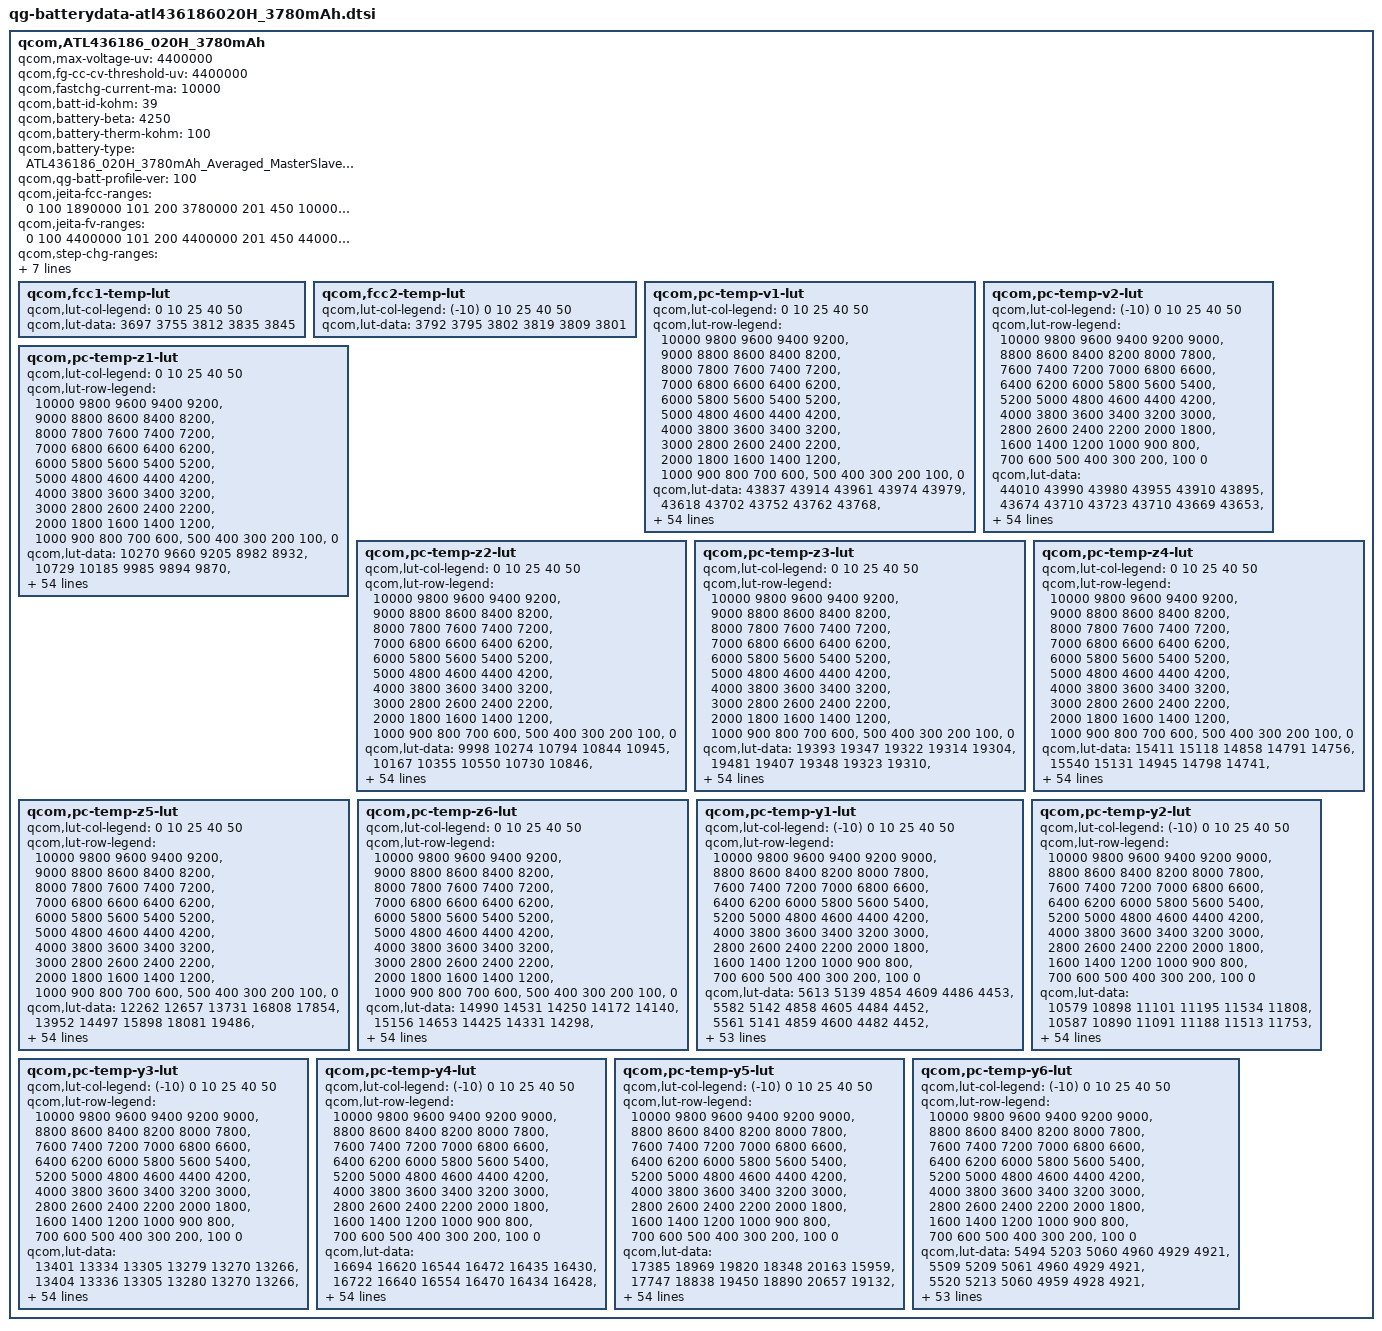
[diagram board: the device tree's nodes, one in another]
qcom,ATL436186_020H_3780mAh {
	/* ATL436186_020H_3780mAh_Averaged_MasterSlave_Feb25th2020 */
	qcom,max-voltage-uv = <4400000>;
	qcom,fg-cc-cv-threshold-uv = <4400000>;
	qcom,fastchg-current-ma = <10000>;
	qcom,batt-id-kohm = <39>;
	qcom,battery-beta = <4250>;
	qcom,battery-therm-kohm = <100>;
	qcom,battery-type =
			"ATL436186_020H_3780mAh_Averaged_MasterSlave_Feb25th2020";
	qcom,qg-batt-profile-ver = <100>;

	qcom,jeita-fcc-ranges = <0  100  1890000
				101 200  3780000
				201 450  10000000
				451 550  1890000>;

	qcom,jeita-fv-ranges = <0   100  4400000
				101 200  4400000
				201 450  4400000
				451 550  4050000>;

	qcom,step-chg-ranges = <3500000  4000000  10000000
				4000001  4200000  8000000
				4200001  4400000  6000000>;
	qcom,ocv-based-step-chg;

	/* COOL = 10 degc, WARM = 45 degC */
	qcom,jeita-soft-thresholds = <0x4ccc 0x20b8>;
	/* COLD = 0 degC, HOT = 55 degC*/
	qcom,jeita-hard-thresholds = <0x58cd 0x181d>;
	/* COOL hys = 13 degC, WARM hys = 42 degC */
	qcom,jeita-soft-hys-thresholds = <0x48d4 0x23c0>;
	qcom,jeita-soft-fcc-ua = <1890000 1890000>;
	qcom,jeita-soft-fv-uv = <4400000 4050000>;

	qcom,fcc1-temp-lut {
		qcom,lut-col-legend = <0 10 25 40 50>;
		qcom,lut-data = <3697 3755 3812 3835 3845>;
	};

	qcom,fcc2-temp-lut {
		qcom,lut-col-legend = <(-10) 0 10 25 40 50>;
		qcom,lut-data = <3792 3795 3802 3819 3809 3801>;
	};

	qcom,pc-temp-v1-lut {
		qcom,lut-col-legend = <0 10 25 40 50>;
		qcom,lut-row-legend = <10000 9800 9600 9400 9200>,
			<9000 8800 8600 8400 8200>,
			<8000 7800 7600 7400 7200>,
			<7000 6800 6600 6400 6200>,
			<6000 5800 5600 5400 5200>,
			<5000 4800 4600 4400 4200>,
			<4000 3800 3600 3400 3200>,
			<3000 2800 2600 2400 2200>,
			<2000 1800 1600 1400 1200>,
			<1000 900 800 700 600>,
			<500 400 300 200 100>,
			<0>;
		qcom,lut-data = <43837 43914 43961 43974 43979>,
			<43618 43702 43752 43762 43768>,
			<43394 43485 43537 43549 43556>,
			<43166 43264 43318 43332 43342>,
			<42938 43039 43095 43113 43125>,
			<42710 42810 42869 42890 42903>,
			<42481 42578 42639 42662 42677>,
			<42256 42346 42406 42431 42450>,
			<42034 42119 42176 42201 42223>,
			<41817 41896 41949 41975 41997>,
			<41609 41677 41725 41751 41771>,
			<41407 41462 41506 41531 41550>,
			<41207 41252 41291 41313 41332>,
			<41011 41053 41083 41103 41121>,
			<40819 40863 40881 40898 40917>,
			<40625 40675 40686 40700 40720>,
			<40431 40487 40499 40510 40529>,
			<40258 40304 40321 40329 40345>,
			<40119 40139 40148 40153 40167>,
			<39977 39988 39986 39986 39997>,
			<39774 39809 39817 39819 39828>,
			<39506 39562 39607 39622 39634>,
			<39289 39314 39366 39391 39406>,
			<39151 39148 39169 39185 39199>,
			<39041 39021 39021 39027 39039>,
			<38943 38908 38896 38893 38903>,
			<38856 38802 38783 38774 38781>,
			<38774 38706 38682 38669 38673>,
			<38695 38620 38590 38572 38573>,
			<38621 38542 38505 38481 38478>,
			<38554 38471 38429 38398 38392>,
			<38493 38405 38359 38322 38312>,
			<38438 38346 38296 38252 38238>,
			<38387 38291 38238 38189 38170>,
			<38341 38243 38188 38137 38109>,
			<38300 38198 38138 38084 38049>,
			<38266 38162 38090 38022 37975>,
			<38227 38123 38040 37953 37891>,
			<38155 38058 37972 37872 37800>,
			<38045 37951 37874 37776 37702>,
			<37922 37829 37759 37666 37594>,
			<37785 37699 37633 37539 37465>,
			<37631 37552 37490 37396 37318>,
			<37448 37375 37320 37231 37158>,
			<37301 37226 37175 37102 37032>,
			<37200 37139 37097 37033 36972>,
			<37176 37110 37072 37016 36954>,
			<37175 37095 37054 37001 36939>,
			<37137 37069 37036 36980 36914>,
			<37063 36993 36930 36851 36764>,
			<36758 36680 36593 36504 36417>,
			<36291 36221 36130 36040 35954>,
			<35695 35625 35535 35440 35357>,
			<34884 34815 34721 34626 34546>,
			<33616 33554 33462 33363 33302>,
			<30000 30000 30000 30000 30000>;
	};

	qcom,pc-temp-v2-lut {
		qcom,lut-col-legend = <(-10) 0 10 25 40 50>;
		qcom,lut-row-legend = <10000 9800 9600 9400 9200 9000>,
			<8800 8600 8400 8200 8000 7800>,
			<7600 7400 7200 7000 6800 6600>,
			<6400 6200 6000 5800 5600 5400>,
			<5200 5000 4800 4600 4400 4200>,
			<4000 3800 3600 3400 3200 3000>,
			<2800 2600 2400 2200 2000 1800>,
			<1600 1400 1200 1000 900 800>,
			<700 600 500 400 300 200>,
			<100 0>;
		qcom,lut-data = <44010 43990 43980 43955 43910 43895>,
			<43674 43710 43723 43710 43669 43653>,
			<43367 43445 43475 43472 43433 43418>,
			<43093 43196 43238 43240 43203 43189>,
			<42851 42966 43012 43017 42980 42968>,
			<42613 42737 42786 42792 42757 42746>,
			<42365 42504 42555 42562 42527 42517>,
			<42121 42270 42323 42330 42297 42288>,
			<41898 42038 42094 42100 42070 42062>,
			<41692 41806 41864 41873 41844 41837>,
			<41486 41578 41638 41648 41621 41615>,
			<41265 41355 41418 41427 41403 41397>,
			<41047 41138 41202 41209 41188 41182>,
			<40862 40936 40996 41001 40980 40975>,
			<40707 40746 40796 40798 40776 40772>,
			<40521 40559 40598 40601 40580 40577>,
			<40232 40377 40403 40410 40392 40389>,
			<39909 40189 40207 40224 40211 40207>,
			<39657 39968 40007 40045 40036 40032>,
			<39447 39713 39804 39870 39866 39866>,
			<39247 39471 39594 39674 39679 39682>,
			<39047 39253 39364 39429 39442 39449>,
			<38856 39052 39141 39188 39206 39213>,
			<38674 38878 38961 39005 39025 39033>,
			<38496 38724 38807 38848 38871 38882>,
			<38358 38586 38671 38714 38738 38751>,
			<38264 38460 38551 38597 38623 38636>,
			<38190 38345 38443 38492 38520 38532>,
			<38129 38232 38342 38395 38426 38435>,
			<38078 38123 38247 38304 38337 38344>,
			<38030 38040 38160 38220 38255 38261>,
			<37982 37980 38078 38142 38179 38186>,
			<37935 37931 38002 38068 38106 38114>,
			<37884 37893 37933 38000 38035 38038>,
			<37832 37863 37868 37935 37964 37959>,
			<37777 37829 37812 37862 37879 37865>,
			<37715 37789 37766 37778 37771 37744>,
			<37646 37742 37719 37690 37659 37617>,
			<37568 37678 37654 37600 37560 37514>,
			<37480 37592 37571 37507 37468 37423>,
			<37378 37484 37472 37409 37367 37324>,
			<37250 37342 37350 37301 37256 37212>,
			<37117 37183 37208 37173 37128 37083>,
			<36996 37011 37048 37022 36979 36931>,
			<36898 36881 36926 36922 36889 36842>,
			<36814 36811 36868 36890 36863 36817>,
			<36773 36779 36838 36869 36848 36802>,
			<36727 36738 36803 36842 36825 36779>,
			<36660 36680 36748 36790 36781 36737>,
			<36517 36561 36624 36620 36609 36535>,
			<36231 36271 36298 36228 36203 36133>,
			<35764 35780 35781 35692 35681 35615>,
			<35118 35133 35110 35007 35009 34946>,
			<34216 34250 34193 34048 34114 34057>,
			<32787 32833 32800 32877 32759 32761>,
			<29558 29605 29729 29539 29540 29544>;
	};

	qcom,pc-temp-z1-lut {
		qcom,lut-col-legend = <0 10 25 40 50>;
		qcom,lut-row-legend = <10000 9800 9600 9400 9200>,
			<9000 8800 8600 8400 8200>,
			<8000 7800 7600 7400 7200>,
			<7000 6800 6600 6400 6200>,
			<6000 5800 5600 5400 5200>,
			<5000 4800 4600 4400 4200>,
			<4000 3800 3600 3400 3200>,
			<3000 2800 2600 2400 2200>,
			<2000 1800 1600 1400 1200>,
			<1000 900 800 700 600>,
			<500 400 300 200 100>,
			<0>;
		qcom,lut-data = <10270 9660 9205 8982 8932>,
			<10729 10185 9985 9894 9870>,
			<10961 10522 10161 10008 9971>,
			<11078 10616 10231 10065 10021>,
			<11137 10656 10248 10073 10030>,
			<11151 10675 10258 10073 10030>,
			<11155 10683 10258 10073 10029>,
			<11157 10687 10253 10071 10028>,
			<11160 10685 10249 10068 10027>,
			<11164 10677 10247 10067 10027>,
			<11163 10670 10245 10066 10026>,
			<11158 10666 10244 10066 10026>,
			<11155 10663 10242 10066 10026>,
			<11156 10660 10241 10066 10026>,
			<11157 10657 10242 10066 10026>,
			<11156 10656 10243 10066 10026>,
			<11151 10657 10244 10066 10027>,
			<11148 10661 10245 10067 10028>,
			<11149 10661 10246 10069 10029>,
			<11150 10662 10249 10070 10030>,
			<11154 10662 10251 10071 10030>,
			<11163 10665 10253 10073 10031>,
			<11167 10668 10256 10075 10032>,
			<11169 10672 10259 10077 10033>,
			<11173 10677 10263 10079 10035>,
			<11179 10682 10268 10081 10037>,
			<11187 10688 10272 10083 10039>,
			<11191 10694 10276 10084 10040>,
			<11188 10695 10280 10086 10041>,
			<11182 10696 10284 10089 10042>,
			<11180 10697 10287 10091 10044>,
			<11182 10699 10290 10093 10046>,
			<11186 10703 10294 10095 10047>,
			<11195 10707 10298 10098 10048>,
			<11210 10711 10302 10101 10050>,
			<11214 10715 10307 10104 10052>,
			<11209 10725 10311 10107 10054>,
			<11204 10735 10316 10109 10057>,
			<11209 10736 10321 10112 10059>,
			<11224 10733 10326 10114 10060>,
			<11232 10731 10331 10116 10062>,
			<11233 10740 10335 10119 10063>,
			<11234 10751 10340 10121 10065>,
			<11236 10753 10345 10123 10065>,
			<11250 10761 10351 10125 10066>,
			<11246 10766 10354 10126 10067>,
			<11246 10761 10358 10127 10067>,
			<11257 10768 10360 10127 10067>,
			<11246 10764 10362 10128 10068>,
			<11264 10770 10369 10131 10069>,
			<11271 10785 10373 10132 10072>,
			<11301 10793 10379 10137 10073>,
			<11283 10797 10389 10144 10076>,
			<11343 10815 10399 10147 10080>,
			<11343 10815 10399 10147 10080>,
			<11343 10815 10399 10147 10080>;
	};

	qcom,pc-temp-z2-lut {
		qcom,lut-col-legend = <0 10 25 40 50>;
		qcom,lut-row-legend = <10000 9800 9600 9400 9200>,
			<9000 8800 8600 8400 8200>,
			<8000 7800 7600 7400 7200>,
			<7000 6800 6600 6400 6200>,
			<6000 5800 5600 5400 5200>,
			<5000 4800 4600 4400 4200>,
			<4000 3800 3600 3400 3200>,
			<3000 2800 2600 2400 2200>,
			<2000 1800 1600 1400 1200>,
			<1000 900 800 700 600>,
			<500 400 300 200 100>,
			<0>;
		qcom,lut-data = <9998 10274 10794 10844 10945>,
			<10167 10355 10550 10730 10846>,
			<10239 10399 10603 10678 10871>,
			<10266 10395 10627 10658 10860>,
			<10276 10383 10590 10661 10840>,
			<10258 10382 10530 10681 10820>,
			<10229 10393 10504 10694 10818>,
			<10222 10402 10503 10691 10838>,
			<10225 10403 10506 10686 10861>,
			<10230 10402 10495 10698 10866>,
			<10468 10399 10479 10712 10863>,
			<10817 10392 10478 10717 10858>,
			<10830 10389 10490 10720 10866>,
			<10488 10389 10497 10723 10887>,
			<10237 10383 10489 10733 10919>,
			<10238 10380 10479 10753 10955>,
			<10250 10394 10485 10763 10976>,
			<10293 10409 10508 10767 10990>,
			<10590 10407 10522 10769 10998>,
			<10856 10392 10525 10764 10996>,
			<10737 10386 10523 10757 10989>,
			<10407 10410 10531 10746 10961>,
			<10271 10437 10570 10711 10841>,
			<10271 10447 10592 10670 10746>,
			<10273 10453 10576 10628 10731>,
			<10283 10454 10553 10595 10727>,
			<10306 10441 10542 10604 10733>,
			<10322 10425 10536 10639 10758>,
			<10324 10424 10535 10657 10785>,
			<10323 10434 10540 10663 10803>,
			<10323 10447 10549 10671 10824>,
			<10329 10467 10557 10698 10870>,
			<10336 10487 10569 10749 10948>,
			<10345 10497 10586 10795 11004>,
			<10355 10502 10622 10833 11059>,
			<10358 10503 10654 10871 11110>,
			<10355 10506 10670 10914 11142>,
			<10351 10511 10681 10958 11183>,
			<10348 10514 10696 10979 11193>,
			<10344 10522 10730 10992 11177>,
			<10338 10526 10756 11000 11154>,
			<10307 10496 10725 10996 11137>,
			<10278 10462 10682 10987 11119>,
			<10264 10453 10689 10977 11087>,
			<10246 10428 10699 10978 11047>,
			<10229 10374 10720 11010 11096>,
			<10188 10355 10691 11025 11117>,
			<10121 10306 10709 11029 11193>,
			<10243 10335 10714 11081 11268>,
			<10479 10337 10724 10961 10999>,
			<10405 10348 10693 10847 10883>,
			<10327 10360 10632 10748 10808>,
			<9992 10290 10623 10696 10740>,
			<10016 10209 10570 10627 10634>,
			<10016 10209 10570 10627 10634>,
			<10016 10209 10570 10627 10634>;
	};

	qcom,pc-temp-z3-lut {
		qcom,lut-col-legend = <0 10 25 40 50>;
		qcom,lut-row-legend = <10000 9800 9600 9400 9200>,
			<9000 8800 8600 8400 8200>,
			<8000 7800 7600 7400 7200>,
			<7000 6800 6600 6400 6200>,
			<6000 5800 5600 5400 5200>,
			<5000 4800 4600 4400 4200>,
			<4000 3800 3600 3400 3200>,
			<3000 2800 2600 2400 2200>,
			<2000 1800 1600 1400 1200>,
			<1000 900 800 700 600>,
			<500 400 300 200 100>,
			<0>;
		qcom,lut-data = <19393 19347 19322 19314 19304>,
			<19481 19407 19348 19323 19310>,
			<19528 19444 19374 19334 19318>,
			<19557 19459 19384 19340 19321>,
			<19571 19467 19381 19338 19320>,
			<19574 19469 19375 19332 19319>,
			<19576 19464 19371 19330 19317>,
			<19574 19458 19367 19329 19315>,
			<19563 19453 19365 19329 19313>,
			<19554 19448 19361 19327 19312>,
			<19555 19445 19358 19323 19311>,
			<19558 19444 19356 19321 19310>,
			<19555 19442 19354 19320 19310>,
			<19544 19439 19353 19319 19309>,
			<19533 19433 19353 19318 19306>,
			<19526 19431 19353 19318 19302>,
			<19521 19432 19352 19317 19300>,
			<19520 19434 19351 19315 19300>,
			<19527 19434 19350 19314 19299>,
			<19535 19434 19349 19312 19299>,
			<19537 19434 19349 19311 19299>,
			<19543 19435 19353 19313 19303>,
			<19546 19436 19361 19324 19317>,
			<19536 19440 19369 19333 19326>,
			<19524 19451 19377 19336 19325>,
			<19524 19456 19381 19338 19323>,
			<19532 19456 19380 19338 19321>,
			<19538 19454 19377 19335 19319>,
			<19538 19451 19374 19332 19317>,
			<19537 19445 19369 19330 19315>,
			<19535 19440 19365 19327 19312>,
			<19531 19436 19361 19324 19309>,
			<19527 19434 19358 19321 19306>,
			<19524 19432 19356 19318 19303>,
			<19521 19430 19355 19315 19301>,
			<19519 19429 19354 19313 19300>,
			<19515 19426 19353 19312 19300>,
			<19511 19424 19352 19312 19301>,
			<19506 19420 19350 19312 19301>,
			<19499 19415 19347 19313 19303>,
			<19494 19410 19343 19314 19304>,
			<19492 19407 19342 19315 19306>,
			<19489 19404 19341 19316 19307>,
			<19483 19400 19338 19319 19308>,
			<19461 19390 19335 19317 19308>,
			<19456 19383 19327 19309 19299>,
			<19436 19385 19328 19304 19295>,
			<19263 19371 19326 19300 19292>,
			<19262 19374 19319 19296 19290>,
			<19261 19369 19326 19308 19301>,
			<19261 19365 19335 19313 19303>,
			<19261 19355 19338 19313 19303>,
			<19264 19362 19329 19315 19304>,
			<19263 19368 19332 19316 19306>,
			<19263 19368 19332 19316 19306>,
			<19263 19368 19332 19316 19306>;
	};

	qcom,pc-temp-z4-lut {
		qcom,lut-col-legend = <0 10 25 40 50>;
		qcom,lut-row-legend = <10000 9800 9600 9400 9200>,
			<9000 8800 8600 8400 8200>,
			<8000 7800 7600 7400 7200>,
			<7000 6800 6600 6400 6200>,
			<6000 5800 5600 5400 5200>,
			<5000 4800 4600 4400 4200>,
			<4000 3800 3600 3400 3200>,
			<3000 2800 2600 2400 2200>,
			<2000 1800 1600 1400 1200>,
			<1000 900 800 700 600>,
			<500 400 300 200 100>,
			<0>;
		qcom,lut-data = <15411 15118 14858 14791 14756>,
			<15540 15131 14945 14798 14741>,
			<15522 15130 14892 14768 14727>,
			<15372 15081 14836 14731 14698>,
			<15215 14972 14795 14714 14687>,
			<15110 14894 14763 14705 14683>,
			<15022 14847 14748 14697 14679>,
			<14959 14816 14739 14690 14675>,
			<14908 14802 14731 14684 14670>,
			<14869 14794 14723 14679 14665>,
			<14839 14788 14717 14674 14661>,
			<14817 14781 14710 14669 14656>,
			<14812 14775 14704 14663 14651>,
			<14820 14769 14698 14658 14647>,
			<14832 14763 14693 14652 14643>,
			<14850 14762 14688 14647 14640>,
			<14880 14770 14686 14643 14636>,
			<14889 14779 14685 14640 14631>,
			<14846 14773 14684 14639 14628>,
			<14800 14754 14688 14641 14629>,
			<14825 14750 14695 14648 14632>,
			<14928 14825 14724 14663 14641>,
			<14993 14913 14779 14695 14664>,
			<15001 14914 14799 14712 14678>,
			<14998 14879 14781 14707 14677>,
			<14983 14850 14758 14697 14673>,
			<14949 14834 14746 14689 14669>,
			<14924 14823 14738 14683 14664>,
			<14914 14821 14734 14678 14660>,
			<14908 14820 14732 14673 14656>,
			<14907 14819 14731 14670 14652>,
			<14908 14821 14731 14669 14650>,
			<14909 14823 14731 14668 14648>,
			<14909 14826 14732 14668 14647>,
			<14909 14829 14734 14669 14646>,
			<14909 14831 14738 14670 14646>,
			<14902 14827 14742 14676 14650>,
			<14892 14820 14745 14686 14661>,
			<14881 14812 14746 14689 14665>,
			<14868 14804 14742 14686 14662>,
			<14851 14792 14736 14681 14659>,
			<14827 14773 14724 14676 14657>,
			<14801 14751 14709 14671 14655>,
			<14776 14733 14701 14668 14655>,
			<14722 14697 14683 14659 14649>,
			<14692 14666 14659 14644 14634>,
			<14706 14660 14649 14639 14629>,
			<14871 14659 14641 14630 14620>,
			<14866 14650 14633 14626 14617>,
			<14863 14655 14638 14628 14623>,
			<14867 14664 14635 14630 14625>,
			<14872 14672 14633 14629 14625>,
			<14872 14667 14638 14627 14624>,
			<14877 14663 14636 14625 14622>,
			<14877 14663 14636 14625 14622>,
			<14877 14663 14636 14625 14622>;
	};

	qcom,pc-temp-z5-lut {
		qcom,lut-col-legend = <0 10 25 40 50>;
		qcom,lut-row-legend = <10000 9800 9600 9400 9200>,
			<9000 8800 8600 8400 8200>,
			<8000 7800 7600 7400 7200>,
			<7000 6800 6600 6400 6200>,
			<6000 5800 5600 5400 5200>,
			<5000 4800 4600 4400 4200>,
			<4000 3800 3600 3400 3200>,
			<3000 2800 2600 2400 2200>,
			<2000 1800 1600 1400 1200>,
			<1000 900 800 700 600>,
			<500 400 300 200 100>,
			<0>;
		qcom,lut-data = <12262 12657 13731 16808 17854>,
			<13952 14497 15898 18081 19486>,
			<15214 16021 17443 19818 21650>,
			<16162 17186 18570 21296 23275>,
			<17097 18170 19329 21536 24003>,
			<18157 19258 19745 21509 24358>,
			<19290 20662 19830 21628 24381>,
			<20511 21771 20008 22343 23971>,
			<21891 22042 20173 22938 23666>,
			<23153 22138 20134 22808 23885>,
			<24239 22299 20112 22359 24494>,
			<25122 22870 20235 22259 25170>,
			<25283 23518 20612 22732 26113>,
			<24901 23610 21090 23419 26820>,
			<24579 23449 21852 24318 26214>,
			<24560 23299 22739 25492 24698>,
			<24597 23117 23372 26450 24419>,
			<24657 22978 23855 27282 26292>,
			<24758 24230 24222 27692 27840>,
			<24963 27807 24600 27046 27691>,
			<27120 29427 24875 25350 27235>,
			<33501 27662 23857 23361 26672>,
			<36732 25045 20915 20755 24954>,
			<32079 23961 19681 19621 23155>,
			<25894 23427 20225 19990 22122>,
			<25017 23670 21187 20786 21421>,
			<26081 25610 22464 21686 21497>,
			<27398 27942 24124 22802 22457>,
			<28893 29059 25372 23931 23556>,
			<30402 29771 26311 25076 24526>,
			<31214 30415 27177 26252 25453>,
			<31859 31149 28012 27490 26246>,
			<32223 31779 28804 28771 27082>,
			<32238 32053 29691 29417 27978>,
			<32222 32216 30909 29665 29280>,
			<32171 32224 31681 29773 30219>,
			<31897 31917 31314 28697 28966>,
			<31589 31417 30242 26131 25565>,
			<31432 30966 29114 25294 24387>,
			<31306 30513 27668 25736 25464>,
			<31237 30105 26683 26472 27140>,
			<31178 29635 26578 27651 29292>,
			<31252 29276 26516 29015 31174>,
			<31626 29252 25441 29682 30555>,
			<31440 30295 26157 28469 30177>,
			<32621 30638 26358 26578 24593>,
			<28667 32814 29500 26931 25216>,
			<11283 24894 31532 29489 30335>,
			<11256 26655 27253 28994 33457>,
			<11252 24276 28331 30163 34171>,
			<11253 21078 30650 32037 33143>,
			<11197 17749 31712 30278 31282>,
			<11126 18743 23249 30719 30746>,
			<11019 19676 23476 30978 30980>,
			<11019 19676 23476 30978 30980>,
			<11019 19676 23476 30978 30980>;
	};

	qcom,pc-temp-z6-lut {
		qcom,lut-col-legend = <0 10 25 40 50>;
		qcom,lut-row-legend = <10000 9800 9600 9400 9200>,
			<9000 8800 8600 8400 8200>,
			<8000 7800 7600 7400 7200>,
			<7000 6800 6600 6400 6200>,
			<6000 5800 5600 5400 5200>,
			<5000 4800 4600 4400 4200>,
			<4000 3800 3600 3400 3200>,
			<3000 2800 2600 2400 2200>,
			<2000 1800 1600 1400 1200>,
			<1000 900 800 700 600>,
			<500 400 300 200 100>,
			<0>;
		qcom,lut-data = <14990 14531 14250 14172 14140>,
			<15156 14653 14425 14331 14298>,
			<15177 14719 14443 14341 14309>,
			<15121 14708 14447 14344 14312>,
			<15058 14667 14434 14340 14311>,
			<15003 14634 14414 14332 14308>,
			<14950 14608 14404 14326 14304>,
			<14907 14588 14397 14323 14301>,
			<14868 14577 14391 14319 14297>,
			<14840 14569 14386 14316 14295>,
			<14826 14563 14381 14312 14292>,
			<14817 14558 14377 14308 14290>,
			<14813 14553 14373 14305 14287>,
			<14809 14548 14370 14302 14285>,
			<14806 14542 14367 14299 14282>,
			<14809 14540 14365 14297 14278>,
			<14818 14544 14364 14294 14275>,
			<14821 14549 14363 14292 14273>,
			<14809 14546 14362 14291 14272>,
			<14796 14539 14364 14292 14272>,
			<14808 14538 14368 14294 14274>,
			<14856 14573 14383 14302 14280>,
			<14885 14613 14414 14324 14298>,
			<14885 14616 14425 14335 14309>,
			<14882 14609 14421 14334 14309>,
			<14877 14602 14416 14332 14306>,
			<14871 14596 14412 14329 14304>,
			<14866 14592 14407 14325 14301>,
			<14864 14589 14404 14321 14298>,
			<14862 14587 14401 14318 14295>,
			<14861 14586 14399 14316 14292>,
			<14863 14587 14397 14314 14289>,
			<14864 14589 14396 14312 14287>,
			<14865 14591 14396 14311 14285>,
			<14867 14593 14398 14310 14284>,
			<14867 14594 14400 14310 14283>,
			<14867 14594 14402 14312 14285>,
			<14866 14593 14405 14317 14291>,
			<14865 14591 14405 14318 14293>,
			<14863 14588 14403 14318 14292>,
			<14861 14584 14400 14317 14292>,
			<14859 14579 14395 14315 14292>,
			<14858 14574 14389 14314 14292>,
			<14856 14569 14386 14314 14293>,
			<14840 14557 14379 14311 14291>,
			<14835 14546 14366 14300 14280>,
			<14833 14546 14362 14295 14275>,
			<14822 14541 14359 14289 14270>,
			<14825 14541 14353 14285 14267>,
			<14833 14546 14359 14292 14276>,
			<14843 14554 14364 14297 14279>,
			<14856 14555 14367 14297 14280>,
			<14867 14566 14367 14299 14281>,
			<14891 14579 14371 14300 14282>,
			<14891 14579 14371 14300 14282>,
			<14891 14579 14371 14300 14282>;
	};

	qcom,pc-temp-y1-lut {
		qcom,lut-col-legend = <(-10) 0 10 25 40 50>;
		qcom,lut-row-legend = <10000 9800 9600 9400 9200 9000>,
			<8800 8600 8400 8200 8000 7800>,
			<7600 7400 7200 7000 6800 6600>,
			<6400 6200 6000 5800 5600 5400>,
			<5200 5000 4800 4600 4400 4200>,
			<4000 3800 3600 3400 3200 3000>,
			<2800 2600 2400 2200 2000 1800>,
			<1600 1400 1200 1000 900 800>,
			<700 600 500 400 300 200>,
			<100 0>;
		qcom,lut-data = <5613 5139 4854 4609 4486 4453>,
			<5582 5142 4858 4605 4484 4452>,
			<5561 5141 4859 4600 4482 4452>,
			<5548 5138 4858 4596 4480 4451>,
			<5541 5134 4856 4592 4478 4450>,
			<5539 5133 4853 4590 4477 4450>,
			<5549 5131 4848 4587 4476 4450>,
			<5563 5129 4842 4585 4475 4450>,
			<5562 5129 4838 4583 4474 4449>,
			<5545 5126 4835 4580 4474 4447>,
			<5535 5124 4832 4578 4473 4446>,
			<5536 5124 4827 4577 4472 4447>,
			<5537 5122 4823 4575 4470 4447>,
			<5539 5121 4821 4574 4470 4447>,
			<5550 5118 4820 4572 4470 4447>,
			<5558 5117 4820 4571 4470 4447>,
			<5560 5127 4820 4572 4470 4447>,
			<5560 5138 4822 4572 4470 4447>,
			<5556 5137 4822 4573 4470 4447>,
			<5550 5127 4821 4574 4471 4448>,
			<5547 5124 4821 4576 4472 4448>,
			<5548 5124 4824 4576 4472 4448>,
			<5549 5126 4826 4577 4472 4449>,
			<5552 5130 4827 4579 4473 4449>,
			<5561 5136 4829 4581 4473 4450>,
			<5570 5140 4831 4583 4474 4451>,
			<5579 5139 4834 4585 4476 4451>,
			<5585 5137 4837 4588 4477 4452>,
			<5579 5139 4841 4591 4478 4452>,
			<5566 5146 4848 4594 4479 4453>,
			<5563 5150 4851 4597 4480 4453>,
			<5559 5154 4853 4600 4482 4454>,
			<5551 5159 4854 4604 4484 4455>,
			<5550 5161 4854 4607 4486 4456>,
			<5556 5162 4855 4611 4488 4458>,
			<5561 5162 4856 4615 4489 4458>,
			<5559 5157 4859 4619 4490 4459>,
			<5555 5152 4862 4623 4491 4460>,
			<5560 5155 4871 4624 4492 4461>,
			<5575 5164 4883 4625 4493 4462>,
			<5582 5167 4888 4627 4495 4463>,
			<5567 5164 4886 4631 4496 4463>,
			<5558 5165 4888 4634 4497 4464>,
			<5581 5178 4892 4640 4499 4465>,
			<5588 5163 4895 4644 4500 4466>,
			<5579 5172 4907 4646 4501 4466>,
			<5597 5165 4900 4650 4502 4466>,
			<5597 5165 4903 4654 4502 4468>,
			<5638 5175 4904 4656 4503 4467>,
			<5637 5176 4909 4658 4503 4468>,
			<5722 5182 4909 4660 4503 4468>,
			<5802 5199 4918 4665 4506 4469>,
			<5999 5220 4916 4671 4508 4470>,
			<6440 5346 4923 4681 4510 4473>,
			<6440 5346 4923 4681 4510 4473>,
			<6440 5346 4923 4681 4510 4473>;
	};

	qcom,pc-temp-y2-lut {
		qcom,lut-col-legend = <(-10) 0 10 25 40 50>;
		qcom,lut-row-legend = <10000 9800 9600 9400 9200 9000>,
			<8800 8600 8400 8200 8000 7800>,
			<7600 7400 7200 7000 6800 6600>,
			<6400 6200 6000 5800 5600 5400>,
			<5200 5000 4800 4600 4400 4200>,
			<4000 3800 3600 3400 3200 3000>,
			<2800 2600 2400 2200 2000 1800>,
			<1600 1400 1200 1000 900 800>,
			<700 600 500 400 300 200>,
			<100 0>;
		qcom,lut-data = <10579 10898 11101 11195 11534 11808>,
			<10587 10890 11091 11188 11513 11753>,
			<10595 10879 11070 11175 11481 11696>,
			<10604 10868 11044 11157 11444 11639>,
			<10612 10857 11017 11136 11403 11584>,
			<10621 10848 10996 11113 11363 11533>,
			<10630 10840 10976 11081 11311 11480>,
			<10639 10830 10955 11051 11264 11433>,
			<10650 10820 10936 11044 11251 11410>,
			<10673 10808 10914 11046 11247 11392>,
			<10698 10802 10904 11044 11242 11376>,
			<10744 10811 10908 11020 11234 11359>,
			<10793 10832 10916 10994 11227 11343>,
			<10791 10866 10931 11000 11228 11330>,
			<10754 10934 10967 11040 11240 11314>,
			<10733 10997 11008 11088 11247 11303>,
			<10770 11068 11064 11140 11246 11302>,
			<10824 11133 11128 11204 11248 11309>,
			<10829 11137 11183 11298 11292 11337>,
			<10812 11095 11236 11421 11410 11407>,
			<10788 11055 11257 11462 11470 11467>,
			<10757 11032 11230 11408 11472 11558>,
			<10716 11010 11191 11350 11476 11666>,
			<10655 10989 11177 11340 11522 11710>,
			<10520 10968 11170 11336 11595 11730>,
			<10362 10946 11169 11335 11630 11752>,
			<10105 10916 11177 11364 11639 11784>,
			<9860 10890 11186 11400 11646 11820>,
			<9786 10887 11191 11417 11670 11856>,
			<9751 10889 11190 11437 11713 11899>,
			<9729 10890 11180 11443 11749 11939>,
			<9712 10843 11139 11445 11777 11976>,
			<9699 10771 11103 11445 11803 12006>,
			<9691 10761 11101 11445 11829 12028>,
			<9685 10796 11105 11451 11852 12052>,
			<9680 10818 11107 11445 11855 12059>,
			<9676 10793 11098 11416 11825 12028>,
			<9673 10743 11080 11393 11794 11998>,
			<9671 10658 11045 11390 11782 12004>,
			<9669 10468 10976 11389 11776 12021>,
			<9667 10230 10887 11379 11772 12015>,
			<9666 9913 10756 11355 11767 11932>,
			<9664 9749 10615 11333 11749 11876>,
			<9663 9708 10495 11285 11708 11873>,
			<9662 9691 10413 11193 11663 11846>,
			<9660 9683 10344 11207 11610 11670>,
			<9659 9678 10297 11200 11562 11627>,
			<9658 9673 10226 11178 11454 11533>,
			<9657 9669 10160 11156 11417 11523>,
			<9654 9666 10110 11116 11448 11504>,
			<9651 9663 10039 11055 11432 11472>,
			<9650 9659 9904 10988 11333 11399>,
			<9648 9654 9774 10991 11236 11296>,
			<9648 9651 9700 11020 11107 11175>,
			<9648 9651 9700 11020 11107 11175>,
			<9648 9651 9700 11020 11107 11175>;
	};

	qcom,pc-temp-y3-lut {
		qcom,lut-col-legend = <(-10) 0 10 25 40 50>;
		qcom,lut-row-legend = <10000 9800 9600 9400 9200 9000>,
			<8800 8600 8400 8200 8000 7800>,
			<7600 7400 7200 7000 6800 6600>,
			<6400 6200 6000 5800 5600 5400>,
			<5200 5000 4800 4600 4400 4200>,
			<4000 3800 3600 3400 3200 3000>,
			<2800 2600 2400 2200 2000 1800>,
			<1600 1400 1200 1000 900 800>,
			<700 600 500 400 300 200>,
			<100 0>;
		qcom,lut-data = <13401 13334 13305 13279 13270 13266>,
			<13404 13336 13305 13280 13270 13266>,
			<13407 13339 13306 13281 13271 13267>,
			<13409 13341 13307 13281 13271 13268>,
			<13412 13343 13308 13282 13272 13269>,
			<13414 13345 13309 13282 13272 13270>,
			<13415 13347 13310 13283 13273 13270>,
			<13416 13349 13312 13283 13273 13270>,
			<13421 13351 13312 13284 13274 13270>,
			<13434 13352 13313 13284 13274 13271>,
			<13442 13353 13314 13285 13275 13271>,
			<13422 13356 13315 13285 13275 13272>,
			<13394 13359 13316 13285 13275 13272>,
			<13389 13356 13316 13286 13275 13273>,
			<13391 13345 13316 13288 13276 13273>,
			<13393 13339 13316 13289 13276 13273>,
			<13388 13342 13313 13290 13277 13274>,
			<13379 13346 13310 13291 13279 13275>,
			<13373 13345 13309 13291 13279 13275>,
			<13369 13337 13308 13290 13280 13276>,
			<13364 13329 13308 13289 13280 13277>,
			<13360 13325 13305 13286 13277 13274>,
			<13356 13322 13300 13282 13274 13270>,
			<13351 13319 13298 13280 13272 13269>,
			<13343 13318 13297 13279 13270 13268>,
			<13338 13316 13296 13278 13270 13268>,
			<13339 13315 13296 13278 13270 13268>,
			<13342 13314 13295 13278 13270 13268>,
			<13347 13312 13295 13278 13270 13268>,
			<13356 13310 13295 13278 13271 13268>,
			<13365 13309 13294 13278 13271 13268>,
			<13373 13306 13293 13278 13271 13268>,
			<13381 13304 13293 13278 13270 13269>,
			<13391 13305 13293 13278 13270 13269>,
			<13406 13311 13292 13278 13271 13269>,
			<13425 13316 13293 13278 13271 13268>,
			<13451 13318 13293 13277 13270 13268>,
			<13484 13321 13294 13277 13269 13267>,
			<13520 13323 13295 13276 13269 13267>,
			<13561 13327 13295 13274 13269 13267>,
			<13608 13332 13296 13275 13269 13268>,
			<13660 13343 13298 13276 13269 13268>,
			<13722 13357 13299 13277 13270 13268>,
			<13798 13368 13301 13277 13270 13268>,
			<13898 13385 13305 13278 13269 13267>,
			<13981 13408 13307 13278 13270 13270>,
			<14066 13433 13309 13279 13272 13271>,
			<14173 13468 13312 13281 13273 13271>,
			<14311 13522 13319 13285 13275 13271>,
			<14673 13589 13329 13285 13273 13270>,
			<15387 13676 13335 13285 13273 13270>,
			<16730 13847 13348 13287 13274 13271>,
			<19422 14291 13383 13291 13275 13271>,
			<24674 15433 13481 13297 13276 13273>,
			<24674 15433 13481 13297 13276 13273>,
			<24674 15433 13481 13297 13276 13273>;
	};

	qcom,pc-temp-y4-lut {
		qcom,lut-col-legend = <(-10) 0 10 25 40 50>;
		qcom,lut-row-legend = <10000 9800 9600 9400 9200 9000>,
			<8800 8600 8400 8200 8000 7800>,
			<7600 7400 7200 7000 6800 6600>,
			<6400 6200 6000 5800 5600 5400>,
			<5200 5000 4800 4600 4400 4200>,
			<4000 3800 3600 3400 3200 3000>,
			<2800 2600 2400 2200 2000 1800>,
			<1600 1400 1200 1000 900 800>,
			<700 600 500 400 300 200>,
			<100 0>;
		qcom,lut-data = <16694 16620 16544 16472 16435 16430>,
			<16722 16640 16554 16470 16434 16428>,
			<16772 16662 16560 16467 16433 16426>,
			<16827 16684 16563 16465 16431 16424>,
			<16872 16700 16565 16463 16430 16422>,
			<16890 16706 16565 16462 16429 16422>,
			<16887 16703 16562 16462 16429 16422>,
			<16884 16698 16557 16461 16429 16422>,
			<16883 16695 16555 16462 16430 16423>,
			<16885 16692 16555 16463 16431 16424>,
			<16889 16691 16555 16465 16432 16424>,
			<16942 16691 16558 16469 16434 16426>,
			<17027 16693 16566 16474 16438 16427>,
			<17070 16714 16578 16479 16441 16429>,
			<17099 16795 16599 16484 16446 16433>,
			<17108 16843 16624 16491 16451 16436>,
			<17016 16843 16657 16503 16456 16441>,
			<16874 16835 16685 16519 16463 16446>,
			<16813 16813 16685 16543 16477 16457>,
			<16782 16754 16670 16575 16501 16474>,
			<16750 16699 16650 16585 16510 16481>,
			<16705 16656 16605 16546 16490 16467>,
			<16657 16619 16553 16498 16463 16447>,
			<16613 16593 16528 16477 16449 16437>,
			<16568 16574 16513 16462 16439 16430>,
			<16550 16558 16506 16458 16436 16428>,
			<16559 16545 16503 16459 16436 16429>,
			<16570 16532 16502 16460 16438 16430>,
			<16576 16512 16501 16463 16440 16431>,
			<16581 16488 16500 16468 16444 16435>,
			<16587 16478 16500 16474 16449 16439>,
			<16596 16484 16498 16479 16456 16444>,
			<16606 16495 16495 16485 16463 16450>,
			<16615 16506 16490 16490 16469 16454>,
			<16625 16517 16481 16494 16473 16457>,
			<16632 16529 16479 16494 16473 16457>,
			<16639 16549 16486 16481 16460 16447>,
			<16644 16569 16497 16466 16445 16436>,
			<16647 16580 16503 16453 16440 16434>,
			<16650 16587 16507 16443 16437 16433>,
			<16650 16588 16511 16442 16435 16433>,
			<16636 16578 16517 16445 16432 16432>,
			<16620 16568 16522 16450 16430 16431>,
			<16614 16563 16525 16453 16428 16427>,
			<16615 16562 16523 16451 16422 16420>,
			<16613 16564 16518 16456 16427 16422>,
			<16627 16574 16527 16464 16431 16427>,
			<16649 16594 16545 16476 16440 16441>,
			<16680 16626 16576 16495 16462 16472>,
			<16773 16666 16611 16492 16462 16446>,
			<16928 16677 16605 16482 16430 16426>,
			<17295 16696 16613 16495 16436 16431>,
			<18563 16866 16657 16525 16454 16445>,
			<24332 17928 16752 16586 16506 16498>,
			<24332 17928 16752 16586 16506 16498>,
			<24332 17928 16752 16586 16506 16498>;
	};

	qcom,pc-temp-y5-lut {
		qcom,lut-col-legend = <(-10) 0 10 25 40 50>;
		qcom,lut-row-legend = <10000 9800 9600 9400 9200 9000>,
			<8800 8600 8400 8200 8000 7800>,
			<7600 7400 7200 7000 6800 6600>,
			<6400 6200 6000 5800 5600 5400>,
			<5200 5000 4800 4600 4400 4200>,
			<4000 3800 3600 3400 3200 3000>,
			<2800 2600 2400 2200 2000 1800>,
			<1600 1400 1200 1000 900 800>,
			<700 600 500 400 300 200>,
			<100 0>;
		qcom,lut-data = <17385 18969 19820 18348 20163 15959>,
			<17747 18838 19450 18890 20657 19132>,
			<18103 18812 19205 19190 21127 22137>,
			<18411 18852 19060 19305 21522 24662>,
			<18626 18918 18991 19291 21795 26391>,
			<18705 18971 18974 19205 21896 27007>,
			<18629 19094 19073 18964 21813 26331>,
			<18510 19255 19222 18609 21627 25304>,
			<18766 19163 19149 18291 21388 24842>,
			<20163 18555 18614 17964 21017 24218>,
			<21032 18009 18042 17605 20541 23551>,
			<19032 17765 17592 16853 19821 22949>,
			<16117 17560 17120 16095 18943 22277>,
			<16345 17065 16488 16048 18051 21384>,
			<19627 15838 15525 16241 17057 20196>,
			<21566 15288 15054 16327 16646 19365>,
			<21325 17934 15379 15963 16689 18762>,
			<20982 21635 16106 15532 16771 18242>,
			<21191 22355 17495 15688 16847 18058>,
			<22316 22435 20149 16465 16869 17992>,
			<23224 22550 21963 17525 17119 18301>,
			<23686 22921 22848 19857 19274 19217>,
			<23988 23459 23408 22065 21698 20457>,
			<23290 23862 23498 22361 21910 21812>,
			<19618 24215 23492 22200 21660 23372>,
			<16438 24526 23534 22071 21408 23966>,
			<14775 24905 23990 22050 21155 23476>,
			<13666 25190 24552 22075 21047 22545>,
			<13635 24764 24798 22051 21119 21378>,
			<13849 22890 24942 21876 21068 19896>,
			<13996 20838 25126 21761 20694 19265>,
			<14033 18639 25610 21706 19522 19158>,
			<14060 16889 26149 21672 18549 19111>,
			<14124 17260 26121 21984 18968 19337>,
			<14308 19696 25472 22832 20290 20169>,
			<14508 21521 24816 23852 21110 20787>,
			<14746 22141 24379 25326 21478 20975>,
			<14986 22550 23907 26231 21632 21128>,
			<15179 22752 23025 24735 21694 21438>,
			<15372 22757 21838 22015 22081 22256>,
			<15402 22360 21056 21454 22681 23441>,
			<14907 20259 20513 22055 23749 25248>,
			<14397 17852 19989 21633 24797 27697>,
			<14093 15614 19667 21203 26044 30188>,
			<13935 14761 20276 22289 27496 29447>,
			<13951 14682 20221 21232 22757 27736>,
			<13926 14690 18886 19253 22810 27775>,
			<14234 14424 17632 18735 22875 24541>,
			<14603 14818 17328 19657 22999 21351>,
			<13616 15527 17751 21342 20705 20460>,
			<12552 15663 18495 22607 27375 29585>,
			<11145 14831 17455 22804 28646 29386>,
			<9957 13010 16230 23779 29324 28727>,
			<9195 10486 14924 24477 27339 28153>,
			<9195 10486 14924 24477 27339 28153>,
			<9195 10486 14924 24477 27339 28153>;
	};

	qcom,pc-temp-y6-lut {
		qcom,lut-col-legend = <(-10) 0 10 25 40 50>;
		qcom,lut-row-legend = <10000 9800 9600 9400 9200 9000>,
			<8800 8600 8400 8200 8000 7800>,
			<7600 7400 7200 7000 6800 6600>,
			<6400 6200 6000 5800 5600 5400>,
			<5200 5000 4800 4600 4400 4200>,
			<4000 3800 3600 3400 3200 3000>,
			<2800 2600 2400 2200 2000 1800>,
			<1600 1400 1200 1000 900 800>,
			<700 600 500 400 300 200>,
			<100 0>;
		qcom,lut-data = <5494 5203 5060 4960 4929 4921>,
			<5509 5209 5061 4960 4929 4921>,
			<5520 5213 5060 4959 4928 4921>,
			<5526 5215 5059 4959 4928 4921>,
			<5530 5216 5058 4958 4928 4921>,
			<5531 5216 5057 4958 4928 4921>,
			<5527 5214 5055 4958 4928 4921>,
			<5521 5210 5053 4958 4929 4922>,
			<5521 5207 5051 4958 4929 4922>,
			<5525 5205 5050 4959 4930 4923>,
			<5530 5204 5049 4959 4931 4923>,
			<5532 5203 5050 4960 4931 4924>,
			<5535 5204 5052 4962 4932 4925>,
			<5541 5208 5055 4963 4934 4926>,
			<5556 5221 5060 4966 4935 4927>,
			<5563 5231 5066 4969 4937 4928>,
			<5536 5233 5073 4973 4939 4930>,
			<5494 5234 5079 4978 4942 4932>,
			<5478 5229 5079 4985 4947 4935>,
			<5470 5207 5074 4993 4954 4941>,
			<5463 5187 5068 4996 4956 4943>,
			<5453 5173 5053 4982 4948 4937>,
			<5444 5162 5036 4966 4938 4928>,
			<5437 5156 5028 4959 4933 4925>,
			<5431 5152 5023 4954 4929 4922>,
			<5429 5150 5021 4953 4928 4922>,
			<5436 5149 5021 4953 4928 4922>,
			<5449 5148 5022 4954 4928 4922>,
			<5463 5146 5023 4955 4929 4923>,
			<5480 5145 5024 4957 4931 4923>,
			<5500 5145 5025 4959 4933 4925>,
			<5522 5150 5026 4961 4934 4927>,
			<5546 5159 5026 4963 4936 4929>,
			<5573 5171 5027 4965 4938 4930>,
			<5604 5188 5027 4967 4940 4931>,
			<5637 5207 5028 4967 4940 4931>,
			<5673 5229 5032 4964 4936 4927>,
			<5711 5253 5039 4959 4931 4924>,
			<5753 5277 5046 4956 4930 4923>,
			<5798 5302 5053 4953 4929 4924>,
			<5845 5328 5061 4953 4929 4924>,
			<5892 5353 5072 4955 4928 4924>,
			<5947 5381 5086 4959 4928 4924>,
			<6021 5417 5102 4961 4927 4922>,
			<6115 5463 5120 4962 4926 4920>,
			<6200 5508 5125 4964 4928 4922>,
			<6283 5549 5138 4968 4931 4925>,
			<6392 5602 5160 4974 4934 4929>,
			<6541 5672 5190 4983 4941 4939>,
			<6922 5760 5227 4983 4941 4930>,
			<7615 5860 5251 4980 4931 4924>,
			<8825 6039 5300 4988 4934 4926>,
			<11227 6535 5388 5002 4940 4931>,
			<16611 7839 5546 5027 4956 4948>,
			<16611 7839 5546 5027 4956 4948>,
			<16611 7839 5546 5027 4956 4948>;
	};
};
